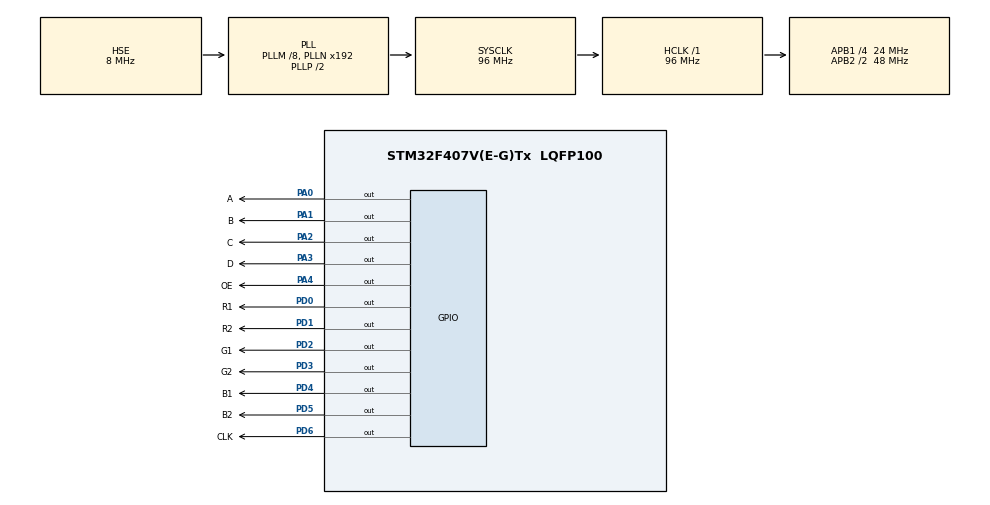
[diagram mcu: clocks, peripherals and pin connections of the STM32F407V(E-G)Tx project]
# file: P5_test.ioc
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Mcu.Family=STM32F4
Mcu.Name=STM32F407V(E-G)Tx
Mcu.Package=LQFP100
NVIC.PriorityGroup=NVIC_PRIORITYGROUP_4
NVIC.TIM1_UP_TIM10_IRQn=true\:0\:0\:false\:false\:true\:true\:true
PA0-WKUP.GPIO_Label=A
PA0-WKUP.GPIO_Speed=GPIO_SPEED_FREQ_HIGH
PA0-WKUP.Signal=GPIO_Output
PA1.GPIO_Label=B
PA1.GPIO_PuPd=GPIO_NOPULL
PA1.GPIO_Speed=GPIO_SPEED_FREQ_HIGH
PA1.PinState=GPIO_PIN_RESET
PA1.Signal=GPIO_Output
PA13.Mode=Serial_Wire
PA13.Signal=SYS_JTMS-SWDIO
PA14.Mode=Serial_Wire
PA14.Signal=SYS_JTCK-SWCLK
PA2.GPIO_Label=C
PA2.GPIO_PuPd=GPIO_NOPULL
PA2.GPIO_Speed=GPIO_SPEED_FREQ_HIGH
PA2.PinState=GPIO_PIN_RESET
PA2.Signal=GPIO_Output
PA3.GPIO_Label=D
PA3.GPIO_PuPd=GPIO_NOPULL
PA3.GPIO_Speed=GPIO_SPEED_FREQ_HIGH
PA3.PinState=GPIO_PIN_RESET
PA3.Signal=GPIO_Output
PA4.GPIO_Label=OE
PA4.Signal=GPIO_Output
PD0.GPIO_Label=R1
PD0.Signal=GPIO_Output
PD1.GPIO_Label=R2
PD1.Signal=GPIO_Output
PD2.GPIO_Label=G1
PD2.Signal=GPIO_Output
PD3.GPIO_Label=G2
PD3.Signal=GPIO_Output
PD4.GPIO_Label=B1
PD4.Signal=GPIO_Output
PD5.GPIO_Label=B2
PD5.Signal=GPIO_Output
PD6.GPIO_Label=CLK
PD6.Signal=GPIO_Output
PH0-OSC_IN.Mode=HSE-External-Oscillator
PH0-OSC_IN.Signal=RCC_OSC_IN
PH1-OSC_OUT.Mode=HSE-External-Oscillator
PH1-OSC_OUT.Signal=RCC_OSC_OUT
ProjectManager.HeapSize=0x200
ProjectManager.StackSize=0x400
ProjectManager.TargetToolchain=MDK-ARM V5.27
RCC.48MHZClocksFreq_Value=48000000
RCC.AHBFreq_Value=96000000
RCC.APB1CLKDivider=RCC_HCLK_DIV4
RCC.APB1Freq_Value=24000000
RCC.APB1TimFreq_Value=48000000
RCC.APB2CLKDivider=RCC_HCLK_DIV2
RCC.APB2Freq_Value=48000000
RCC.APB2TimFreq_Value=96000000
RCC.CortexFreq_Value=96000000
RCC.HCLKFreq_Value=96000000
RCC.HSE_VALUE=8000000
RCC.HSI_VALUE=16000000
RCC.PLLM=8
RCC.PLLSourceVirtual=RCC_PLLSOURCE_HSE
RCC.SYSCLKFreq_VALUE=96000000
RCC.SYSCLKSource=RCC_SYSCLKSOURCE_PLLCLK
RCC.VCOOutputFreq_Value=192000000
TIM1.CounterMode=TIM_COUNTERMODE_DOWN
TIM1.Period=40
VP_TIM1_VS_ClockSourceINT.Mode=Internal
board=custom

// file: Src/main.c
/* USER CODE BEGIN Header */
/**
  ******************************************************************************
  * @file           : main.c
  * @brief          : Main program body
  ******************************************************************************
  * @attention
  *
  * <h2><center>&copy; Copyright (c) 2021 STMicroelectronics.
  * All rights reserved.</center></h2>
  *
  * This software component is licensed by ST under BSD 3-Clause license,
  * the "License"; You may not use this file except in compliance with the
  * License. You may obtain a copy of the License at:
  *                        opensource.org/licenses/BSD-3-Clause
  *
  ******************************************************************************
  */
/* USER CODE END Header */
#include "main.h"

/* USER CODE BEGIN Includes */
#include "font.h"
#include "P5_Lib.h"
#include "mario.h"

/* USER CODE END Includes */

TIM_HandleTypeDef htim1;

void SystemClock_Config(void);
static void MX_GPIO_Init(void);
static void MX_TIM1_Init(void);

int main(void)
{

  /* MCU Configuration--------------------------------------------------------*/

  /* Reset of all peripherals, Initializes the Flash interface and the Systick. */
  HAL_Init();

  /* Configure the system clock */
  SystemClock_Config();

  /* Initialize all configured peripherals */
  MX_GPIO_Init();
  MX_TIM1_Init();
  /* USER CODE BEGIN 2 */
  HAL_TIM_Base_Start_IT(&htim1);
  /* USER CODE END 2 */

  /* Infinite loop */
  while (1)
  {

    /* USER CODE BEGIN 3 */
		drawImage(64,0,64,32,(uint16_t *)mario);
		giaimap5fullmau();
  }
  /* USER CODE END 3 */
}

void SystemClock_Config(void)
{
  RCC_OscInitTypeDef RCC_OscInitStruct = {0};
  RCC_ClkInitTypeDef RCC_ClkInitStruct = {0};

  /** Configure the main internal regulator output voltage
  */
  __HAL_RCC_PWR_CLK_ENABLE();
  __HAL_PWR_VOLTAGESCALING_CONFIG(PWR_REGULATOR_VOLTAGE_SCALE1);
  /** Initializes the RCC Oscillators according to the specified parameters
  * in the RCC_OscInitTypeDef structure.
  */
  RCC_OscInitStruct.OscillatorType = RCC_OSCILLATORTYPE_HSE;
  RCC_OscInitStruct.HSEState = RCC_HSE_ON;
  RCC_OscInitStruct.PLL.PLLState = RCC_PLL_ON;
  RCC_OscInitStruct.PLL.PLLSource = RCC_PLLSOURCE_HSE;
  RCC_OscInitStruct.PLL.PLLM = 8;
  RCC_OscInitStruct.PLL.PLLN = 192;
  RCC_OscInitStruct.PLL.PLLP = RCC_PLLP_DIV2;
  RCC_OscInitStruct.PLL.PLLQ = 4;
  if (HAL_RCC_OscConfig(&RCC_OscInitStruct) != HAL_OK)
  {
    Error_Handler();
  }
  /** Initializes the CPU, AHB and APB buses clocks
  */
  RCC_ClkInitStruct.ClockType = RCC_CLOCKTYPE_HCLK|RCC_CLOCKTYPE_SYSCLK
                              |RCC_CLOCKTYPE_PCLK1|RCC_CLOCKTYPE_PCLK2;
  RCC_ClkInitStruct.SYSCLKSource = RCC_SYSCLKSOURCE_PLLCLK;
  RCC_ClkInitStruct.AHBCLKDivider = RCC_SYSCLK_DIV1;
  RCC_ClkInitStruct.APB1CLKDivider = RCC_HCLK_DIV4;
  RCC_ClkInitStruct.APB2CLKDivider = RCC_HCLK_DIV2;

  if (HAL_RCC_ClockConfig(&RCC_ClkInitStruct, FLASH_LATENCY_3) != HAL_OK)
  {
    Error_Handler();
  }
}

static void MX_TIM1_Init(void)
{

  TIM_ClockConfigTypeDef sClockSourceConfig = {0};
  TIM_MasterConfigTypeDef sMasterConfig = {0};

  htim1.Instance = TIM1;
  htim1.Init.Prescaler = 0;
  htim1.Init.CounterMode = TIM_COUNTERMODE_DOWN;
  htim1.Init.Period = 40;
  htim1.Init.ClockDivision = TIM_CLOCKDIVISION_DIV1;
  htim1.Init.RepetitionCounter = 0;
  htim1.Init.AutoReloadPreload = TIM_AUTORELOAD_PRELOAD_DISABLE;
  if (HAL_TIM_Base_Init(&htim1) != HAL_OK)
  {
    Error_Handler();
  }
  sClockSourceConfig.ClockSource = TIM_CLOCKSOURCE_INTERNAL;
  if (HAL_TIM_ConfigClockSource(&htim1, &sClockSourceConfig) != HAL_OK)
  {
    Error_Handler();
  }
  sMasterConfig.MasterOutputTrigger = TIM_TRGO_RESET;
  sMasterConfig.MasterSlaveMode = TIM_MASTERSLAVEMODE_DISABLE;
  if (HAL_TIMEx_MasterConfigSynchronization(&htim1, &sMasterConfig) != HAL_OK)
  {
    Error_Handler();
  }

}

static void MX_GPIO_Init(void)
{
  GPIO_InitTypeDef GPIO_InitStruct = {0};

  /* GPIO Ports Clock Enable */
  __HAL_RCC_GPIOH_CLK_ENABLE();
  __HAL_RCC_GPIOA_CLK_ENABLE();
  __HAL_RCC_GPIOD_CLK_ENABLE();

  /*Configure GPIO pin Output Level */
  HAL_GPIO_WritePin(GPIOA, A_Pin|B_Pin|C_Pin|D_Pin
                          |OE_Pin, GPIO_PIN_RESET);

  /*Configure GPIO pin Output Level */
  HAL_GPIO_WritePin(GPIOD, R1_Pin|R2_Pin|G1_Pin|G2_Pin
                          |B1_Pin|B2_Pin|CLK_Pin, GPIO_PIN_RESET);

  /*Configure GPIO pins : A_Pin B_Pin C_Pin D_Pin */
  GPIO_InitStruct.Pin = A_Pin|B_Pin|C_Pin|D_Pin;
  GPIO_InitStruct.Mode = GPIO_MODE_OUTPUT_PP;
  GPIO_InitStruct.Pull = GPIO_NOPULL;
  GPIO_InitStruct.Speed = GPIO_SPEED_FREQ_HIGH;
  HAL_GPIO_Init(GPIOA, &GPIO_InitStruct);

  /*Configure GPIO pin : OE_Pin */
  GPIO_InitStruct.Pin = OE_Pin;
  GPIO_InitStruct.Mode = GPIO_MODE_OUTPUT_PP;
  GPIO_InitStruct.Pull = GPIO_NOPULL;
  GPIO_InitStruct.Speed = GPIO_SPEED_FREQ_LOW;
  HAL_GPIO_Init(OE_GPIO_Port, &GPIO_InitStruct);

  /*Configure GPIO pins : R1_Pin R2_Pin G1_Pin G2_Pin
                           B1_Pin B2_Pin CLK_Pin */
  GPIO_InitStruct.Pin = R1_Pin|R2_Pin|G1_Pin|G2_Pin
                          |B1_Pin|B2_Pin|CLK_Pin;
  GPIO_InitStruct.Mode = GPIO_MODE_OUTPUT_PP;
  GPIO_InitStruct.Pull = GPIO_NOPULL;
  GPIO_InitStruct.Speed = GPIO_SPEED_FREQ_LOW;
  HAL_GPIO_Init(GPIOD, &GPIO_InitStruct);

}

void Error_Handler(void)
{
}

/************************ (C) COPYRIGHT STMicroelectronics *****END OF FILE****/
